# STM32H723 register map
File version: 1.6
CPU: CM7 r0p1, little endian, MPU, FPU, 4 interrupt priority bits
Registers are 32-bit, read-write, reset 0x0 unless marked. A register's access mark holds for its fields unless they carry their own. Offsets are from the block's base; [hi:lo] are bit positions; {n}, {i} and the like mark numbered series; 'fields as' and 'values as' point back to an identical list.

## CRC — Cryptographic processor
Base 0x58024C00
0x00 DR reset 0xFFFFFFFF — Data register
  [31:0] DR — Data Register
0x04 IDR — Independent Data register
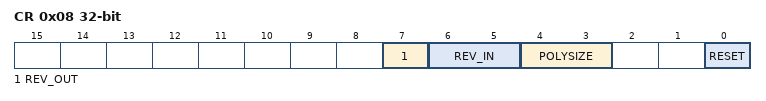
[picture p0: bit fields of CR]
0x08 CR access per field — Control register
  [7] REV_OUT rw — Reverse output data
  [6:5] REV_IN rw — Reverse input data
  [4:3] POLYSIZE rw — Polynomial size
  [0] RESET wo — RESET bit
0x10 INIT — Initial CRC value
  [31:0] CRC_INIT — Programmable initial CRC value
0x14 POL reset 0x4C11DB7 — CRC polynomial
  [31:0] POL — Programmable polynomial

## DBGMCU — Microcontroller Debug Unit
Base 0x5C001000
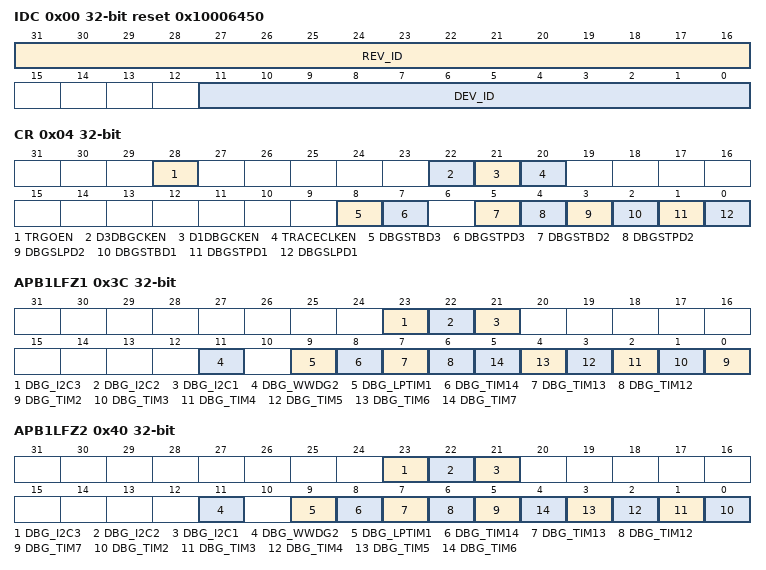
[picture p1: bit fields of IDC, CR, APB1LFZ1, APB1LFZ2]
0x00 IDC ro reset 0x10006450 — DBGMCU Identity Code Register
  [31:16] REV_ID — Revision
  [11:0] DEV_ID — Device ID
0x04 CR — DBGMCU Configuration Register
  [28] TRGOEN — External trigger output enable
  [22] D3DBGCKEN — D3 debug clock enable
  [21] D1DBGCKEN — D1 debug clock enable
  [20] TRACECLKEN — Trace port clock enable
  [8] DBGSTBD3 — Allow debug in D3 Standby mode
  [7] DBGSTPD3 — Allow debug in D3 Stop mode
  [5] DBGSTBD2 — Allow D2 domain debug in Standby mode
  [4] DBGSTPD2 — Allow D2 domain debug in Stop mode
  [3] DBGSLPD2 — Allow D2 domain debug in Sleep mode
  [2] DBGSTBD1 — Allow D1 domain debug in Standby mode
  [1] DBGSTPD1 — Allow D1 domain debug in Stop mode
  [0] DBGSLPD1 — Allow D1 domain debug in Sleep mode
0x34 APB3FZ1 — DBGMCU APB3 peripheral freeze register CPU1
  [6] WWDG1 — WWDG1 stop in debug
0x38 APB3FZ2 — DBGMCU APB3 peripheral freeze register CPU2
  [6] WWDG1 — WWDG1 stop in debug
0x3C APB1LFZ1 — DBGMCU APB1L peripheral freeze register
  [23] DBG_I2C3 — I2C3 SMBUS timeout stop in debug
  [22] DBG_I2C2 — I2C2 SMBUS timeout stop in debug
  [21] DBG_I2C1 — I2C1 SMBUS timeout stop in debug
  [11] DBG_WWDG2 — WWDG2 stop in debug
  [9] DBG_LPTIM1 — LPTIM1 stop in debug
  [8] DBG_TIM14 — TIM14 stop in debug
  [7] DBG_TIM13 — TIM13 stop in debug
  [6] DBG_TIM12 — TIM12 stop in debug
  [n-2] DBG_TIM{n} (n=2..7) — TIM{n} stop in debug
0x40 APB1LFZ2 — DBGMCU APB1L peripheral freeze register CPU2
  [23] DBG_I2C3 — I2C3 SMBUS timeout stop in debug
  [22] DBG_I2C2 — I2C2 SMBUS timeout stop in debug
  [21] DBG_I2C1 — I2C1 SMBUS timeout stop in debug
  [11] DBG_WWDG2 — WWDG2 stop in debug
  [9] DBG_LPTIM1 — LPTIM1 stop in debug
  [8] DBG_TIM14 — TIM14 stop in debug
  [7] DBG_TIM13 — TIM13 stop in debug
  [6] DBG_TIM12 — TIM12 stop in debug
  [5] DBG_TIM7 — TIM4 stop in debug
  [n-2] DBG_TIM{n} (n=2..6) — TIM{n} stop in debug
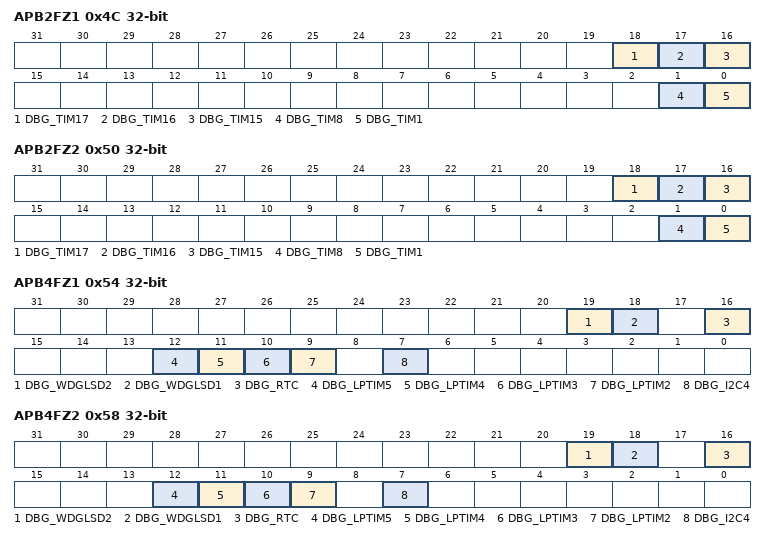
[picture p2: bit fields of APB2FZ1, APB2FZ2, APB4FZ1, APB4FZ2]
0x4C APB2FZ1 — DBGMCU APB2 peripheral freeze register
  [18] DBG_TIM17 — TIM17 stop in debug
  [17] DBG_TIM16 — TIM16 stop in debug
  [16] DBG_TIM15 — TIM15 stop in debug
  [1] DBG_TIM8 — TIM8 stop in debug
  [0] DBG_TIM1 — TIM1 stop in debug
0x50 APB2FZ2 — DBGMCU APB2 peripheral freeze register CPU2
  fields as APB2FZ1
0x54 APB4FZ1 — DBGMCU APB4 peripheral freeze register
  [19] DBG_WDGLSD2 — Independent watchdog for D2 stop in debug
  [18] DBG_WDGLSD1 — Independent watchdog for D1 stop in debug
  [16] DBG_RTC — RTC stop in debug
  [12] DBG_LPTIM5 — LPTIM5 stop in debug
  [11] DBG_LPTIM4 — LPTIM4 stop in debug
  [10] DBG_LPTIM3 — LPTIM2 stop in debug
  [9] DBG_LPTIM2 — LPTIM2 stop in debug
  [7] DBG_I2C4 — I2C4 SMBUS timeout stop in debug
0x58 APB4FZ2 — DBGMCU APB4 peripheral freeze register CPU2
  [19] DBG_WDGLSD2 — LS watchdog for D2 stop in debug
  [18] DBG_WDGLSD1 — LS watchdog for D1 stop in debug
  [16] DBG_RTC — RTC stop in debug
  [12] DBG_LPTIM5 — LPTIM5 stop in debug
  [11] DBG_LPTIM4 — LPTIM4 stop in debug
  [10] DBG_LPTIM3 — LPTIM2 stop in debug
  [9] DBG_LPTIM2 — LPTIM2 stop in debug
  [7] DBG_I2C4 — I2C4 SMBUS timeout stop in debug

## DCMI — Digital camera interface
Base 0x48020000
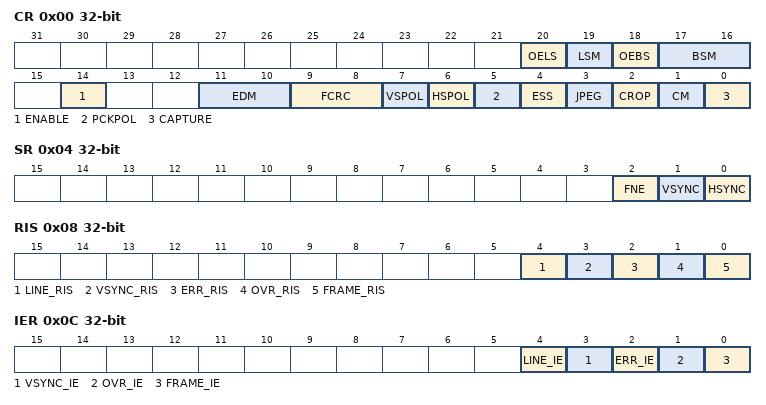
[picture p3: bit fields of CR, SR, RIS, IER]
0x00 CR — control register 1
  [20] OELS — Odd/Even Line Select (Line Select Start)
  [19] LSM — Line Select mode
  [18] OEBS — Odd/Even Byte Select (Byte Select Start)
  [17:16] BSM — Byte Select mode
  [14] ENABLE — DCMI enable
  [11:10] EDM — Extended data mode
  [9:8] FCRC — Frame capture rate control
  [7] VSPOL — Vertical synchronization polarity
  [6] HSPOL — Horizontal synchronization polarity
  [5] PCKPOL — Pixel clock polarity
  [4] ESS — Embedded synchronization select
  [3] JPEG — JPEG format
  [2] CROP — Crop feature
  [1] CM — Capture mode
  [0] CAPTURE — Capture enable
0x04 SR ro — status register
  [2] FNE — FIFO not empty
  [1] VSYNC
  [0] HSYNC
0x08 RIS ro — raw interrupt status register
  [4] LINE_RIS — Line raw interrupt status
  [3] VSYNC_RIS — VSYNC raw interrupt status
  [2] ERR_RIS — Synchronization error raw interrupt status
  [1] OVR_RIS — Overrun raw interrupt status
  [0] FRAME_RIS — Capture complete raw interrupt status
0x0C IER — interrupt enable register
  [4] LINE_IE — Line interrupt enable
  [3] VSYNC_IE — VSYNC interrupt enable
  [2] ERR_IE — Synchronization error interrupt enable
  [1] OVR_IE — Overrun interrupt enable
  [0] FRAME_IE — Capture complete interrupt enable
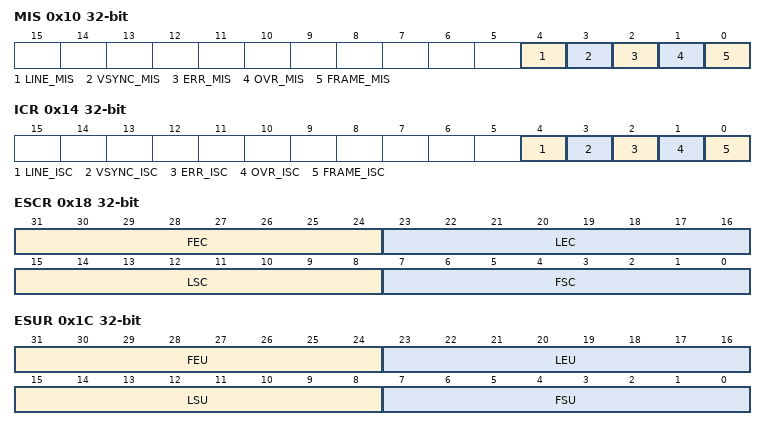
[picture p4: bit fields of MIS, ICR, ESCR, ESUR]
0x10 MIS ro — masked interrupt status register
  [4] LINE_MIS — Line masked interrupt status
  [3] VSYNC_MIS — VSYNC masked interrupt status
  [2] ERR_MIS — Synchronization error masked interrupt status
  [1] OVR_MIS — Overrun masked interrupt status
  [0] FRAME_MIS — Capture complete masked interrupt status
0x14 ICR wo — interrupt clear register
  [4] LINE_ISC — line interrupt status clear
  [3] VSYNC_ISC — Vertical synch interrupt status clear
  [2] ERR_ISC — Synchronization error interrupt status clear
  [1] OVR_ISC — Overrun interrupt status clear
  [0] FRAME_ISC — Capture complete interrupt status clear
0x18 ESCR — embedded synchronization code register
  [31:24] FEC — Frame end delimiter code
  [23:16] LEC — Line end delimiter code
  [15:8] LSC — Line start delimiter code
  [7:0] FSC — Frame start delimiter code
0x1C ESUR — embedded synchronization unmask register
  [31:24] FEU — Frame end delimiter unmask
  [23:16] LEU — Line end delimiter unmask
  [15:8] LSU — Line start delimiter unmask
  [7:0] FSU — Frame start delimiter unmask
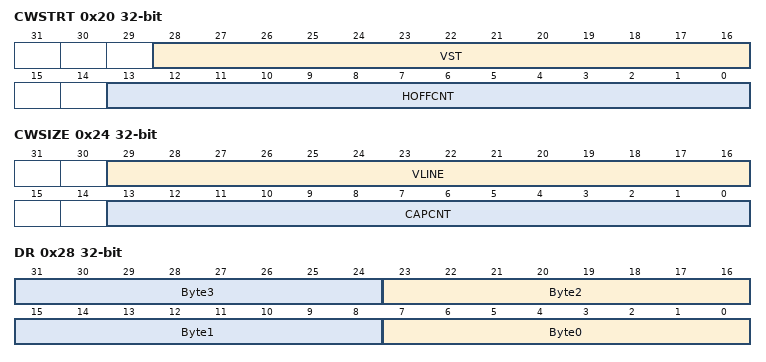
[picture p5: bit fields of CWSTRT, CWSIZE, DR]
0x20 CWSTRT — crop window start
  [28:16] VST — Vertical start line count
  [13:0] HOFFCNT — Horizontal offset count
0x24 CWSIZE — crop window size
  [29:16] VLINE — Vertical line count
  [13:0] CAPCNT — Capture count
0x28 DR ro — data register
  [8n+7:8n] Byte{n} (n=0..3) — Data byte {n}
